# STM32MP23_CM33 register map
File version: 1.2
CPU: CM33 r0p1, little endian, MPU, FPU, vendor SysTick, 8 interrupt priority bits
Registers are 32-bit, read-write, reset 0x0 unless marked. A register's access mark holds for its fields unless they carry their own. Offsets are from the block's base; [hi:lo] are bit positions; {n}, {i} and the like mark numbered series.

## USB3DR (part 2 of 4) — USB3DR register block
Base 0x48300000
Same registers: USB3DR_S 0x58300000
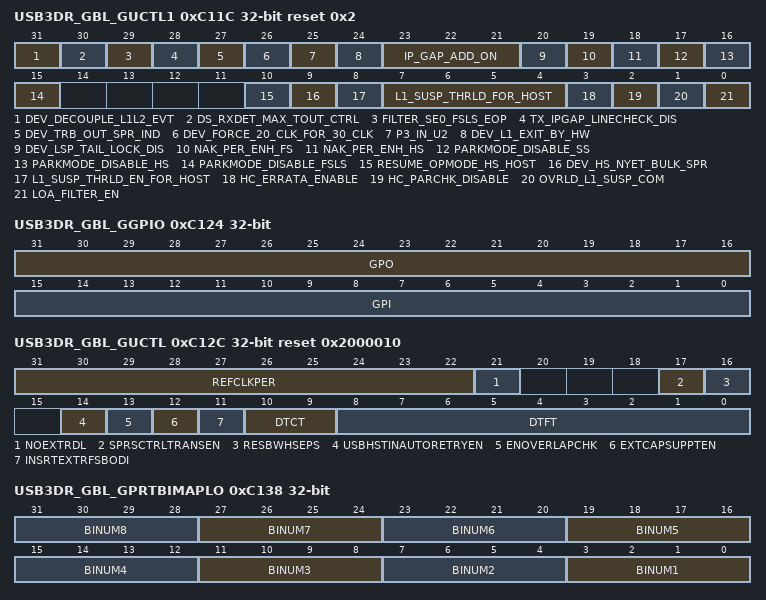
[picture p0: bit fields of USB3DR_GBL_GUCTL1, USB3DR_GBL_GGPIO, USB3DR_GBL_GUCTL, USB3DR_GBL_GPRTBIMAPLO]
0xC11C USB3DR_GBL_GUCTL1 reset 0x2 — USB3DR global user control register 1
  [31] DEV_DECOUPLE_L1L2_EVT — DEV_DECOUPLE_L1L2_EVT This bit is applicable for device mode only. If this feature is enabled, L1 suspend and wake events have individual controls to enable/mask them. This feature must be enabled in order to get L1 (LPM) events separately and not combined with L2 events when operating in 2.0 speeds.
    0=Default behavior, no change in device events L1/L2U3, events are not decoupled (old behavior of v2.90a and before); 1=Feature enabled, L1 and L2 events are separated when operating in 2.0 mode. Separate event enable bits for L1 suspend and wake events.
  [30] DS_RXDET_MAX_TOUT_CTRL — DS_RXDET_MAX_TOUT_CTRL This bit is used to control the tsubRxDetectTimeoutDFP/sub timer for the SuperSpeed link. This bit is used only in Host mode. For more details, refer to ECN020 of [USB3].
    0=Default behavior; 12ms is used as tsubRxDetectTimeoutDFP/sub; 1=120ms is used as the tsubRxDetectTimeoutDFP/sub
  [29] FILTER_SE0_FSLS_EOP — FILTER_SE0_FSLS_EOP This bit is applicable for FS/LS operation. If this feature is enabled, then SE0 on the linestate is validated for 2 consecutive utmi/ulpi clock edges for EOP detection. This feature is applicable only in FS in device mode and FS/LS mode of operation in host mode. Device mode: FS - If GUCTL1.FILTER_SE0_FSLS_EOP is set, then for device LPM handshake, the core ignores single SE0 glitch on the linestate during transmit. Only two or more SE0 areconsidered as a valid EOP on FS. Host mode: FS/LS - If GUCTL1.FILTER_SE0_FSLS_EOP is set, then the core ignores single SE0 glitch on the linestate during transmit. Only 2 or more SE0 are considered as a valid EOP on FS/LS port. Enable this feature if the LineState has SE0 glitches during transmission. This bit is quasi-static, that is it must not be changed during device operation.
    0=Default behavior, no change in linestate check for SE0 detection in FS/LS; 1=Feature enabled, FS/LS SE0 is filtered for 2 clocks for detecting EOP
  [28] TX_IPGAP_LINECHECK_DIS — TX_IPGAP_LINECHECK_DIS This bit is applicable for HS operation of u2mac. If this feature is enabled, then the 2.0 MAC operating in HS ignores the UTMI/ULPI linestate during the transmit of a token (during token-to-token and token-to-data IPGAP). When enabled, the controller implements a fixed 40-bit TxEndDelay after the packet is given on UTMI and ignores the linestate during this time. This feature is applicable only in HS mode of operation. Device mode: If GUCTL1.TX_IPGAP_LINECHECK_DIS is set, then for device LPM handshake, the core ignores the linestate after TX and wait for fixed clocks (40 bit times equivalent) after transmitting ACK on utmi. Host mode: If GUCTL1.TX_IPGAP_LINECHECK_DIS is set, then the ipgap between token-to-token or token-to-data is extended by a 40-bit time delay (TXENDDELAY), and linestate is ignored during this 40-bit time delay. Enable this bit if the linestate does not reflect the expected line state (J) during transmission. This bit is quasi-static, that is, it must not be changed during device operation.
    0=Default behavior, no change in linestate check; 1=Feature enabled, 2.0 MAC disables linestate check during HS transmit
  [27] DEV_TRB_OUT_SPR_IND — DEV_TRB_OUT_SPR_IND This bit is applicable for Device mode only (and ignored in Host mode). If the device application (software/hardware) wants to know if a short packet was received for an OUT in the TRB status itself, then this feature can be enabled, so that a bit is set in the TRB writeback in the buf_size dword. Bit[26] of buf_size is set during an OUT transfer TRB write back if this is the last TRB used for that transfer descriptor. This bit is quasi-static, that is, it must not be changed during device operation.
    0=Default behavior, no change in TRB status dword; 1=Feature enabled, OUT TRB status indicates short packet
  [26] DEV_FORCE_20_CLK_FOR_30_CLK — DEV_FORCE_20_CLK_FOR_30_CLK This bit is applicable (and to be set) for device mode only (DCFG.Speed different SS). In the 3.0 device core, if the core is programmed to operate in 2.0 only (that is, device speed is programmed to 2.0 speeds in DCFG[Speed]), then setting this bit makes the internal 2.0 (utmi/ulpi) clock to be routed as the 3.0 (pipe) clock. Enabling this feature disables the pipe3 clock when forcibly operating in 2.0 device mode. Note: When using this feature, all pipe3 inputs must be in inactive mode. In particular, the pipe3 clocks must not be running and the pipe3_phystatus_async must be tied to 0. This bit should not be set if the core is programmed to operate in SuperSpeed mode (even when it falls back to 2.0). Note: This bit is quasi-static, that is it must not be changed during operation. Note: If the parameter 'USB3DR_REMOVE_PIPE_CLK_MUX_FOR_20_MODE' is enabled, the muxing of 2.0 clock/signals to pipe_clk/signals must be done outside the controller for this feature to work.
    0=Default behavior, uses 3.0 clock when operating in 2.0 mode; 1=Feature enabled
  [25] P3_IN_U2 — P3_IN_U2 Setting this bit enables P3 Power state when the SuperSpeed link is in U2. Another Power saving option. Check with the PHY vendor before enabling this option. When setting this bit to 1 in order to enable P3 in P2, GUSB3PIPECTL[27] should be set to 0 to make sure that the U2 exit is attempted in P0. This bit should be set only when GCTL.SOFITPSYNC=1 or GFLADJ.GFLADJ_REFCLK_LPM_SEL=1.
    0=Default behavior. When SuperSpeed link is in U2, PowerState P2 is attempted on the PIPE interface.; 1=When SuperSpeed link is in U2, PowerState P3 is attempted if GUSB3PIPECTL[17] is set
  [24] DEV_L1_EXIT_BY_HW — DEV_L1_EXIT_BY_HW This bit is applicable for Device mode (2.0) only. This field enables device controller sending remote wakeup for L1 if the device becomes ready for sending/accepting data when in L1 state. If the host expects the device to send remote wakeup signaling to resume after going into L1 in flow controlled state, then this bit can be set to send the remote wake signal automatically when the device controller becomes ready. This hardware remote wake feature is applicable only to bulk and interrupt transfers, and not for Isoch/Control When control transfers are in progress, the LPM is rejected (NYET response). Only after control transfers are completed (either with ACK/STALL), LPM is accepted For Isoch transfers, the host needs to do the wakeup and start the transfer. Device controller does not remote-wakeup when Isoch endpoints get ready. The device software needs to keep the GUSB2PHYCFG[EnblSlpM] reset in order to keep the PHY clock to be running for keeping track of SOF intervals. When L1 hibernation is enabled, the controller does not do automatic exit for hibernation requests through L1. This bit is quasi-static, that is, it must not be changed during device operation.
    0=Default behavior, disables device L1 hardware exit logic; 1=feature enabled
  [23:21] IP_GAP_ADD_ON — This register field is used to add up to the default inter packet gap setting in the USB 2.0 MAC. This should be programmed to a non zero value only in case the default inter packet delay calculations in the USB 2.0 MAC module needs to be increased.
  [20] DEV_LSP_TAIL_LOCK_DIS — DEV_LSP_TAIL_LOCK_DIS This is a bug fix for STAR 9000716195 that affects the CSP mode for OUT endpoints in device mode. The issue is that tail TRB index is not synchronized with the cache scratchpad bytecount update. If the fast-forward request comes in-between the bytecount update on a newly fetched TRB and the tail-index write update in TPF, the RDP works on an incorrect tail index and misses the byte count decrement for the newly fetched TRB in the fast-forwarding process. This fix needs to be present all the times.
    0=Default behavior, enables device lsp lock logic for tail TRB update; 1=Bug fix disabled
  [19] NAK_PER_ENH_FS — NAK_PER_ENH_FS If a periodic endpoint is present, and if a bulk endpoint which is also active is being NAKed by the device, then this may result in a decrease in performance of another Full speed bulk endpoint which is ACKed by the device. Setting this bit to 1 enables the host controller to schedule more transactions to the async endpoints (bulk/control) and hence improves the performance of the bulk endpoint. This control bit should be enabled only if the existing performance with the default setting is not sufficient for the FullSpeed application. Setting this bit only controls, and is only required for full speed transfers.
    1=Enables performance enhancement for FS async endpoints in the presence of NAKs; 0=Enhancement not applied
  [18] NAK_PER_ENH_HS — NAK_PER_ENH_HS If a periodic endpoint is present, and if a bulk endpoint which is also active is being NAKed by the device, then this may result in decrease in performance of another high-speed bulk endpoint which is ACKed by the device. Setting this bit to 1 enables the host controller to schedule more transactions to the async endpoints (bulk/control) and hence improves the performance of the bulk endpoint. This control bit should be enabled only if the existing performance with the default setting is not sufficient for the HighSpeed application. Setting this bit only controls, and is only required for high-speed transfers.
    1=Enables performance enhancement for HS async endpoints in the presence of NAKs; 0=Enhancement not applied
  [17] PARKMODE_DISABLE_SS — PARKMODE_DISABLE_SS This bit is used only in Host mode, and is for debug purpose only. When this bit is set to 1 all SS bus instances in park mode are disabled.
  [16] PARKMODE_DISABLE_HS — PARKMODE_DISABLE_HS This bit is used only in Host mode. When this bit is set to 1 all HS bus instances park mode are disabled. To improve performance in park mode, the xHCI scheduler queues in three requests of 4 packets each for high-speed asynchronous endpoints in a micro-frame. But if a device is slow and if it NAKs more than 3 times, then it is rescheduled only in the next micro-frame. This may decrease the performance of a slow device even further. In a few high-speed devices (such as Sandisksup/sup Cruzer Blade 4GB VID:1921, PID:21863 and Flex Drive VID:3744, PID:8552) when an IN request is sent within 900ns of the ACK of the previous packet, these devices send a NAK. When connected to these devices, if required, the software can disable the park mode if a performance drop is observed in the system. When park mode is disabled, pipelining of multiple packet is disabled and instead one packet at a time is requested by the scheduler. This allows up to 12 NAKs in a micro-frame and improves performance of these slow devices.
  [15] PARKMODE_DISABLE_FSLS — PARKMODE_DISABLE_FSLS This bit is used only in host mode, and is for debug purpose only. When this bit is set to 1 all FS/LS bus instances in park mode are disabled.
  [10] RESUME_OPMODE_HS_HOST — RESUME_OPMODE_HS_HOST This bit is used only in host mode, and is for USB 2.0 opmode behavior in HS Resume. When this bit is set to '1', the UTMI/ULPI opmode is changed to 'normal' along with HS terminations after EOR. This option is to support certain legacy UTMI/ULPI PHYs. When this bit is set to '0', the UTMI/ULPI opmode is changed to 'normal' 2us after HS terminations change after EOR. This is the default behavior.
  [9] DEV_HS_NYET_BULK_SPR — DEV_HS_NYET_BULK_SPR This bit is applicable for device mode only (and ignored in Host mode) to be used in 2.0 operation. If this bit is set, the device core sends NYET response instead of ACK response for a successfully received bulk OUT short packet. If NYET is sent after receiving short packet, then the host would PING before sending the next OUT. This improves the performance as well as clears up the buffer/cache on the host side. Internal to the device core, short packet (SPR1) processing takes some time, and during this time, the USB is flow controlled. With NYET response instead of ACK on short packet, the host does not send another OUT-DATA without pinging in HS mode. This bit is quasi-static, that is, it must not be changed during device operation.
    0=Default behavior, no change in device response; 1=Feature enabled, HS bulk OUT short packet gets NYET response
  [8] L1_SUSP_THRLD_EN_FOR_HOST — L1_SUSP_THRLD_EN_FOR_HOST This bit is used only in Host mode. The host controller asserts the utmi_l1_suspend_n and utmi_sleep_n output signals as follows: The controller asserts the utmi_l1_suspend_n signal to put the PHY into deep Low-power mode in L1 when both of the following are true: The HIRD/BESL value used is greater than or equal to the value in L1_SUSP_THRLD_FOR_HOST field. The L1_SUSP_THRLD_EN_FOR_HOST bit is set to 1. The controller asserts utmi_sleep_n on L1 when one of the following is true: The HIRD/BESL value used is less than the value in L1_SUSP_THRLD_FOR_HOST field. The L1_SUSP_THRLD_EN_FOR_HOST bit is set to 0.
  [7:4] L1_SUSP_THRLD_FOR_HOST — L1_SUSP_THRLD_FOR_HOST This field is effective only when the L1_SUSP_THRLD_EN_FOR_HOST bit is set to 1. For more details, refer to the description of the L1_SUSP_THRLD_EN_FOR_HOST bit.
  [3] HC_ERRATA_ENABLE — Host ELD Enable (HELDEn) When this bit is set to 1, it enables the exit latency delta (ELD) support defined in the [xHCI] errata. This bit is used only in the host mode. This bit has to be set to 1 in Host mode.
  [2] HC_PARCHK_DISABLE — Host parameter check disable (HParChkDisable) When this bit is set to 0 (by default), the xHC checks that the input slot/EP context fields comply to the xHCI specification. Upon detection of a parameter error during command execution, the xHC generates an event TRB with completion code indicating 'PARAMETER ERROR'. When the bit is set to '1', the xHC does not perform parameter checks and does not generate 'PARAMETER ERROR' completion code.
  [1] OVRLD_L1_SUSP_COM — OVRLD_L1_SUSP_COM If this bit is set, the utmi_l1_suspend_com_n is overloaded with the utmi_sleep_n signal. This bit is usually set if the PHY stops the port clock during L1 sleep condition. Note: The recommended connection for the SUSPENDM/SLEEPM signals to the PHY with respect to this bit is as follows. Note: For non-zero ports: Note: Connect: Note: - utmi_sleep_n[n] to SLEEPM[n] Note: - (utmi_suspend_n[n] & utmi_l1_suspend_n[n]) to SUSPENDM[n] Note: - USB2 PHYCLK[n] to utmi_clk[n] Note: GUCTL1.OVRLD_L1_SUSP_COM impacts only Port0. Note: For Port0: Note: For Synopsys PHY, GUSB2PHYCFGn.U2_FREECLK_EXISTS=1. With this connection, the PHY keeps PLL active so that FREECLK is always available irrespective of suspend/sleep. Note: - Connect USB2 PHY COMMONONN to 0. Note: - Connect utmi_sleep_n[0] to SLEEPM[0]. Note: - Connect (utmi_suspend_n[0] & utmi_l1_suspend_n[0]) to SUSPENDM[0]. Note: - Connect USB2 PHY FREECLK to utmi_clk[0]. Note: - Leave utmi_suspend_com_n, utmi_l1_suspend_com_n unconnected. Note: - GUCTL1.OVRLD_L1_SUSP_COM can be set to any value. Note: For Third Party PHY, Note: GUSB2PHYCFGn.U2_FREECLK_EXISTS=0. With this connection the PHY can shut off all the clocks when the required conditions are met (such as GUSB2PHYCFGn[8,6], GUCTL1[1], GFLADJ[23], GCTL[10], suspend condition, HW LPM enable). Note: - Connect -utmi_suspend_com_n to SUSPENDM[0] (or equivalent). Note: - Connect -utmi_l1_suspend_com_n to SLEEPM[0] (or equivalent). Note: - Connect PHYCLK0 (first port clock) to utmi_clk[0]. Note: - Leave utmi_suspend_n[0], utmi_l1_suspend_ n[0], utmi_sleep_n[0] unconnected. Note: - Set GUCTL1.OVRLD_L1_SUSP_COM to 0b1.
  [0] LOA_FILTER_EN — LOA_FILTER_EN If this bit is set, the USB 2.0 port babble is checked at least three consecutive times before the port is disabled. This prevents false triggering of the babble condition when using low quality cables. Note: This bit is valid only in host mode.
0xC120 USB3DR_GBL_GSNPSID ro reset 0x5533330B — USB3DR global Synopsys ID register
  [31:0] SYNOPSYSID — Synopsys ID SynopsysID[31:16] indicates core identification number. 0x5533 is ASCII for U3 (USB3DR). SynopsysID[15:0] indicates the release number.
0xC124 USB3DR_GBL_GGPIO — USB3DR global general purpose input/output register
  [31:16] GPO — General purpose output This field value is driven out on the gp_out[15:0] core output port.
  [15:0] GPI ro — General purpose input This field read value reflects the gp_in[15:0] core input value. Note: Register bit-bash test should not check for reset value of this field since its not predictable; depends on the gp_in port.
0xC128 USB3DR_GBL_GUID reset 0x12345678 — USB3DR global user ID register
  [31:0] USERID — USERID Application programmable ID field.
0xC12C USB3DR_GBL_GUCTL reset 0x2000010 — USB3DR global user control register
  [31:22] REFCLKPER — REFCLKPER This field indicates in terms of nano seconds the period of ref_clk. The default value of this register is set to 0x8 (8ns/125MHz). This field needs to be updated during power-on initialization, if GCTL.SOFITPSYNC or GFLADJ.GFLADJ_REFCLK_LPM_SEL is set to 1. The programmable maximum value is 62ns, and the minimum value is 8ns. A reference clock with a period that is an integer multiple must be used, so that ITP can meet the jitter margin of 32ns. The allowable ref_clk frequencies whose period is not integer multiple are 16/17/19.2/24/39.7MHz. This field must not be set to 0 at any time. If this feature should never be used, this field should be kept at its default value 0x8.
  [21] NOEXTRDL — No extra delay between SOF and the first Packet(NoExtrDl) Some HS devices misbehave when the host sends a packet immediately after a SOF. However, adding an extra delay between a SOF and the first packet can reduce the USB data rate and performance. This bit is used to control whether the host must wait for 2 microseconds before it sends the first packet after a SOF, or not. User can set this bit to 1 to improve the performance if those problematic devices are not a concern in the user's host environment.
    0=Host waits for 2 microseconds after a SOF before it sends the first USB packet; 1=Host does not wait after a SOF before it sends the first USB packet
  [17] SPRSCTRLTRANSEN — Sparse control transaction enable Some devices are slow in responding to control transfers. Scheduling multiple transactions in one microframe/frame can cause these devices to misbehave. If this bit is set to 1, the host controller schedules transactions for a control transfer in different microframes/frames.
  [16] RESBWHSEPS — Reserving 85% bandwidth for HS periodic EPs (ResBwHSEPS) By default, HC reserves 80% of the bandwidth for periodic EPs. If this bit is set, the bandwidth is relaxed to 85% to accommodate two high-speed, high-bandwidth ISOC EPs. USB 2.0 required 80% bandwidth allocated for ISOC traffic. If two high-bandwidth ISOC devices (HD webcams) are connected, and if each requires 1024-bytes X 3 packets per microframe, then the bandwidth required is around 82%. If this bit is set, then it is possible to connect two webcams of 1024Bytes X 3 paylod per microframe each. Otherwise the resolution of the webcams may have to be reduced. This bit is valid in Host and DRD configuration and is used in Host mode operation only. Ignore this bit in device mode.
  [14] USBHSTINAUTORETRYEN — Host IN auto retry (USBHstInAutoRetryEn) When set, this field enables the auto retry feature. For IN transfers (non-isochronous) that encounter data packets with CRC errors or internal overrun scenarios, the auto retry feature causes the Host core to reply to the device with a non-terminating retry ACK (that is, an ACK transaction packet with Retry = 1 and NumP different 0). If the auto retry feature is disabled (default), the core responds with a terminating retry ACK (that is, an ACK transaction packet with Retry=1 and NumP=0). Note: When enabling auto retry feature, if the system latency is large enough to cause the internal PSQ full (PSQ can be full as the result of messages not being processed because of pending fetches before flushing the TxQ due to NRDY/ERDY conditions), then the host controller can generate a transaction error.
    0=Auto retry disabled; 1=Auto retry enabled
  [13] ENOVERLAPCHK — Enable check for LFPS overlap during remote Ux exit: If this bit is set to,
    1=The SuperSpeed link when exiting U1/U2/U3 waits for either the remote link LFPS or TS1/TS2 training symbols before it confirms that the LFPS handshake is complete. This is done to handle the case where the LFPS glitch causes the link to start exiting from the low power state. Looking for the LFPS overlap makes sure that the link partner also sees the LFPS.; 0=When the link exits U1/U2/U3 because of a remote exit, it does not look for an LFPS overlap
  [12] EXTCAPSUPPTEN — External extended capability support enable (ExtCapSuptEN) When set, this field enables extended capabilities to be implemented outside the core. When the ExtCapSupEN is set and the debug capability is enabled, the next capability pointer in 'Debug Capability' returns 16. A read to the first dword of the last internal extended capability (the 'xHCI supported Protocol Capability for USB 3.0' when the debug capability is not enabled) returns a value of 4 in the next capability pointer field. This indicates to software that there is another capability, 4 dwords after this capability (for example, at address N+16 where N is the address of this dword). If enabled, an external address decoder that snoops the xHC slave interface must be implemented. If it sees an access to N+16 or greater, the slave access is re-routed to a piece of hardware which returns the external capability pointer register of the new capability and also handles reads/writes to this new capability and the side effects. If disabled, a read to the first dword of the last internal extended capability returns 0 in the next capability pointer field. This indicates there are no more capabilities.
  [11] INSRTEXTRFSBODI — Insert extra delay between FS bulk OUT transactions (InsrtExtrFSBODl) Some FS devices are slow to receive bulk OUT data and can get stuck when there are consecutive bulk OUT transactions with short inter-transaction delays. This bit is used to control whether the host inserts extra delay between consecutive bulk OUT transactions to a FS endpoint. Note: Setting this bit to one reduces the bulk OUT transfer performance for most of the FS devices.
    0=Host does not insert extra delay between consecutive bulk OUT transactions to a FS endpoint; 1=Host inserts about 12 us extra delay between consecutive bulk OUT transactions to a FS endpoint to work around the device issue
  [10:9] DTCT — Device timeout coarse tuning (DTCT) This field is a Host mode parameter which determines how long the host waits for a response from device before considering a timeout. The core first checks the DTCT value. If it is 0, then the timeout value is defined by the DTFT. If it is non-zero, then it uses the following timeout values: Note: When the system latency is larger than the programmed DTCT/DTFT value, if the host controller is not able to accept certain transactions on the bus (because of system bus delays), the controller may not release header credits which in turn can cause the host to report a transaction error. Therefore, program this value to be larger than the system delay.
    0=0 us → use DTFT value instead; 1=0.5ms; 2=1.5ms; 3=6.5ms
  [8:0] DTFT — Device timeout fine tuning (DTFT) This field is a Host mode parameter which determines how long the host waits for a response from device before considering a timeout. For the DTFT field to take effect, DTCT must be set to 0b00. The DTFT value is the number of 125MHz clocks 256 to count before considering a device timeout. The minimum value of DTFT is 2. For example, if the mac3_clk is 125MHz clk (8ns period), this is calculated as follows: (DTFT value) 256 (8ns) Quick Reference: - if DTFT = 0x2, 2 × 256 × 8 = 4 us timeout - if DTFT = 0x5, 5 × 256 × 8 = 10 us timeout - if DTFT = 0xA, 10 × 256 × 8 = 20 us timeout - if DTFT = 0x10, 16 × 256 × 8 = 32 us timeout - if DTFT = 0x19, 25 × 256 × 8 = 51 us timeout - if DTFT = 0x31, 49 × 256 × 8 = 100 us timeout - if DTFT = 0x62, 98 × 256 × 8 = 200 us timeout Note: When SSIC is enabled, in HS_G1_G2_G3 mode, and ssic_soc_pa_clk_freq = 0b01, then DTFT value must be calculated for 156.25 MHz clock, for example, for equivalent delay of 32 us DTFT value must be 0x14. Note: When the system latency is larger than the programmed DTCT/DTFT value, if the host controller is not able to accept certain transactions on the bus (because of system bus delays), the controller may not release header credits which in turn can cause the host to report a transaction error. Therefore, program this value to be larger than the system delay.
0xC130 USB3DR_GBL_GBUSERRADDRLO ro — USB3DR global bus error address register - low
  [31:0] BUSERRADDR — Bus address low (BusAddrLo) This register contains the lower 32 bits of the first bus address that encountered a device bus error. It is valid when the GSTS.BusErrAddrVld field is 1. It can only be cleared by resetting the core. Note: Only supported in AHB and AXI configurations.
0xC134 USB3DR_GBL_GBUSERRADDRHI ro — USB3DR gobal bus error address register - high
  [31:0] BUSERRADDR — Bus address high (BusAddrHi) This register contains the higher 32 bits of the first bus address that encountered a device bus error. It is valid when the GSTS.BusErrAddrVld field is 1. It can only be cleared by resetting the core. Note: Only supported in AHB and AXI configurations.
0xC138 USB3DR_GBL_GPRTBIMAPLO — USB3DR global SS port to bus instance mapping register - low
  [4n-1:4n-4] BINUM{n} (n=1..8) — SS USB instance number for port {n}. Application programmable ID field.
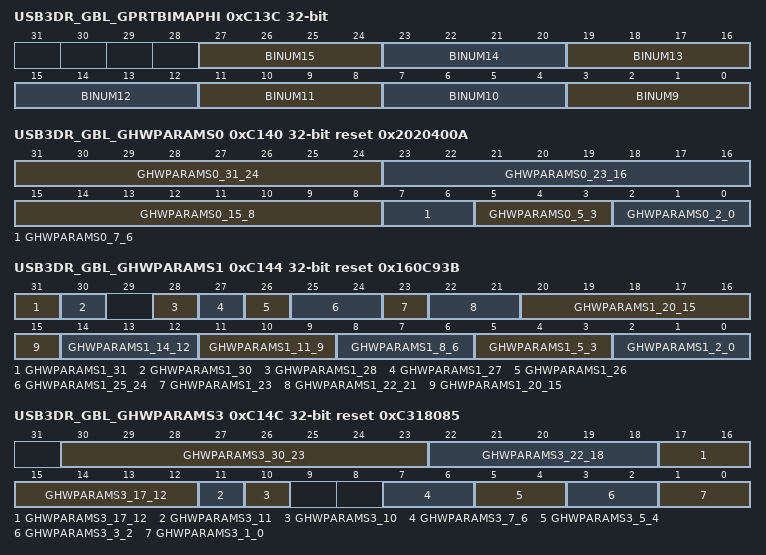
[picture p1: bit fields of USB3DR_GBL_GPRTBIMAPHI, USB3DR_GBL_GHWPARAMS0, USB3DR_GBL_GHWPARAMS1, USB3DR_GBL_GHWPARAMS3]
0xC13C USB3DR_GBL_GPRTBIMAPHI — USB3DR global SS port to bus instance mapping register - high
  [4n-33:4n-36] BINUM{n} (n=9..15) — SS USB instance number for port {n}. Application programmable ID field.
0xC140 USB3DR_GBL_GHWPARAMS0 ro reset 0x2020400A — USB3DR global hardware parameters register 0
  [31:24] GHWPARAMS0_31_24 — USB3DR_AWIDTH
  [23:16] GHWPARAMS0_23_16 — USB3DR_SDWIDTH
  [15:8] GHWPARAMS0_15_8 — USB3DR_MDWIDTH
  [7:6] GHWPARAMS0_7_6 — USB3DR_SBUS_TYPE
  [5:3] GHWPARAMS0_5_3 — USB3DR_MBUS_TYPE
  [2:0] GHWPARAMS0_2_0 — USB3DR_MODE
0xC144 USB3DR_GBL_GHWPARAMS1 ro reset 0x160C93B — USB3DR global hardware parameters register 1
  [31] GHWPARAMS1_31 — USB3DR_EN_DBC
  [30] GHWPARAMS1_30 — USB3DR_RM_OPT_FEATURES
  [28] GHWPARAMS1_28 — USB3DR_RAM_BUS_CLKS_SYNC
  [27] GHWPARAMS1_27 — USB3DR_MAC_RAM_CLKS_SYNC
  [26] GHWPARAMS1_26 — USB3DR_MAC_PHY_CLKS_SYNC
  [25:24] GHWPARAMS1_25_24 — USB3DR_EN_PWROPT
  [23] GHWPARAMS1_23 — USB3DR_SPRAM_TYP
  [22:21] GHWPARAMS1_22_21 — USB3DR_NUM_RAMS
  [20:15] GHWPARAMS1_20_15 — USB3DR_DEVICE_NUM_INT
  [14:12] GHWPARAMS1_14_12 — USB3DR_ASPACEWIDTH
  [11:9] GHWPARAMS1_11_9 — USB3DR_REQINFOWIDTH
  [8:6] GHWPARAMS1_8_6 — USB3DR_DATAINFOWIDTH
  [5:3] GHWPARAMS1_5_3 — USB3DR_BURSTWIDTH-1
  [2:0] GHWPARAMS1_2_0 — USB3DR_IDWIDTH-1
0xC148 USB3DR_GBL_GHWPARAMS2 ro reset 0x12345678 — USB3DR global hardware parameters register 2
  [31:0] GHWPARAMS2_31_0 — USB3DR_USERID
0xC14C USB3DR_GBL_GHWPARAMS3 ro reset 0xC318085 — USB3DR global hardware parameters register 3
  [30:23] GHWPARAMS3_30_23 — USB3DR_CACHE_TOTAL_XFER_RESOURCES
  [22:18] GHWPARAMS3_22_18 — USB3DR_NUM_IN_EPS
  [17:12] GHWPARAMS3_17_12 — USB3DR_NUM_EPS
  [11] GHWPARAMS3_11 — USB3DR_ULPI_CARKIT
  [10] GHWPARAMS3_10 — USB3DR_VENDOR_CTL_INTERFACE
  [7:6] GHWPARAMS3_7_6 — USB3DR_HSPHY_DWIDTH
  [5:4] GHWPARAMS3_5_4 — USB3DR_FSPHY_INTERFACE
  [3:2] GHWPARAMS3_3_2 — USB3DR_HSPHY_INTERFACE
  [1:0] GHWPARAMS3_1_0 — USB3DR_SSPHY_INTERFACE
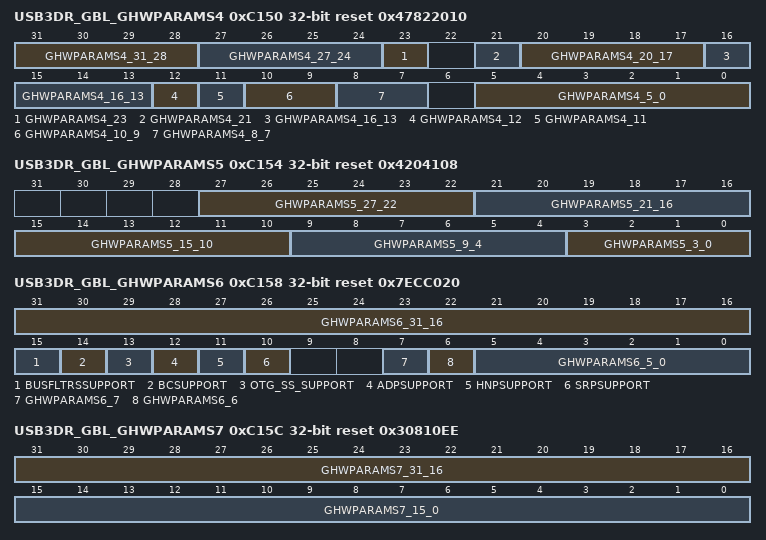
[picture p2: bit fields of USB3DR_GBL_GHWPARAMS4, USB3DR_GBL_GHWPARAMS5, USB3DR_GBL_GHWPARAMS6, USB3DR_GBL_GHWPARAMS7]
0xC150 USB3DR_GBL_GHWPARAMS4 ro reset 0x47822010 — USB3DR global hardware parameters register 4
  [31:28] GHWPARAMS4_31_28 — USB3DR_BMU_LSP_DEPTH
  [27:24] GHWPARAMS4_27_24 — USB3DR_BMU_PTL_DEPTH-1
  [23] GHWPARAMS4_23 — USB3DR_EN_ISOC_SUPT
  [21] GHWPARAMS4_21 — USB3DR_EXT_BUFF_CONTROL
  [20:17] GHWPARAMS4_20_17 — USB3DR_NUM_SS_USB_INSTANCES
  [16:13] GHWPARAMS4_16_13 — USB3DR_HIBER_SCRATCHBUFS Number of external scratchpad buffers the core requires to save its internal state in the device mode. Each buffer is assumed to be 4KBytes. The scratchpad buffer array must have this many buffer pointers.
  [12] GHWPARAMS4_12 — USB3DR_EN_SSIC Note: When the USB3DR_NUM_SSIC_PORTS parameter is set to zero, this bit is Reserved.
    0=if USB3DR_EN_SSIC=0; 1=if USB3DR_EN_SSIC different 0
  [11] GHWPARAMS4_11 — USB3DR_SSIC_NON_SNPS_MPHY This field indicates whether Synopsys M-PHY or a third party M-PHY is used with SSIC ports. Note: When the USB3DR_NUM_SSIC_PORTS parameter is set to zero, this bit is Reserved.
    0=Synopsys M-PHY; 1=Third party M-PHY
  [10:9] GHWPARAMS4_10_9 — USB3DR_SSIC_GEAR This field indicates USB3DR_SSIC_GEAR parameter value chosen by the user. Note: When the USB3DR_NUM_SSIC_PORTS parameter is set to zero, this field is Reserved.
    1=HS-G1; 2=HS-G2; 3=HS-G3
  [8:7] GHWPARAMS4_8_7 — USB3DR_NUM_SSIC_NUM_LANE This bit indicates USB3DR_SSIC_NUM_LANE parameter value chosen by the user. Note: When the USB3DR_NUM_SSIC_PORTS parameter is set to zero, this field is Reserved.
    0=4 lanes; 1=1 lane; 2=2 lanes
  [5:0] GHWPARAMS4_5_0 — USB3DR_CACHE_TRBS_PER_TRANSFER
0xC154 USB3DR_GBL_GHWPARAMS5 ro reset 0x4204108 — USB3DR global hardware parameters register 5
  [27:22] GHWPARAMS5_27_22 — USB3DR_DFQ_FIFO_DEPTH
  [21:16] GHWPARAMS5_21_16 — USB3DR_DWQ_FIFO_DEPTH
  [15:10] GHWPARAMS5_15_10 — USB3DR_TXQ_FIFO_DEPTH
  [9:4] GHWPARAMS5_9_4 — USB3DR_RXQ_FIFO_DEPTH
  [3:0] GHWPARAMS5_3_0 — USB3DR_BMU_BUSGM_DEPTH
0xC158 USB3DR_GBL_GHWPARAMS6 ro reset 0x7ECC020 — USB3DR global hardware parameters register 6
  [31:16] GHWPARAMS6_31_16 — USB3DR_RAM0_DEPTH
  [15] BUSFLTRSSUPPORT — USB3DR_EN_BUS_FILTERS
  [14] BCSUPPORT — USB3DR_EN_BC
  [13] OTG_SS_SUPPORT — OTG 3.0 support enabled This bit indicates whether the parameter USB3DR_EN_OTG is set to 2. In other words, it indicates whether the USB3DR core supports OTG 3.0.
    0=No OTG 3.0 support; 1=Supports OTG 3.0
  [12] ADPSUPPORT — USB3DR_EN_ADP
  [11] HNPSUPPORT — RSP/HNP support enabled The application uses this bit to determine the USB3DR RSP/HNP support. This bit is enabled only if HNP mode was specified for HNP mode of operation in coreConsultant (parameter USB3DR_EN_OTG is not 0, and USB3DR_MODE is DRD). Otherwise, it reads as 0.
    0=B_0x0_USB3DR_EN_OTG_EQUAL2 (RSP and HNP support is not enabled. The only exception for this rule is for SSPC-OTG devices where RSP support is not enabled, but HNP support is enabled (refer to the OCFG.SSPC-OTG bit.)); 1=B_0x1_USB3DR_EN_OTG_EQUAL2 (RSP and HNP support is enabled)
  [10] SRPSUPPORT — SRP support enabled The application uses this bit to determine the USB3DR SRP support. This bit is 1 when the parameter USB3DR_EN_OTG is not 0.
    0=SRP support is not enabled;; 1=SRP support is enabled;
  [7] GHWPARAMS6_7 — USB3DR_EN_FPGA
  [6] GHWPARAMS6_6 — USB3DR_EN_DBG_PORTS
  [5:0] GHWPARAMS6_5_0 — USB3DR_PSQ_FIFO_DEPTH
0xC15C USB3DR_GBL_GHWPARAMS7 ro reset 0x30810EE — USB3DR global hardware parameters register 7
  [31:16] GHWPARAMS7_31_16 — USB3DR_RAM2_DEPTH
  [15:0] GHWPARAMS7_15_0 — USB3DR_RAM1_DEPTH
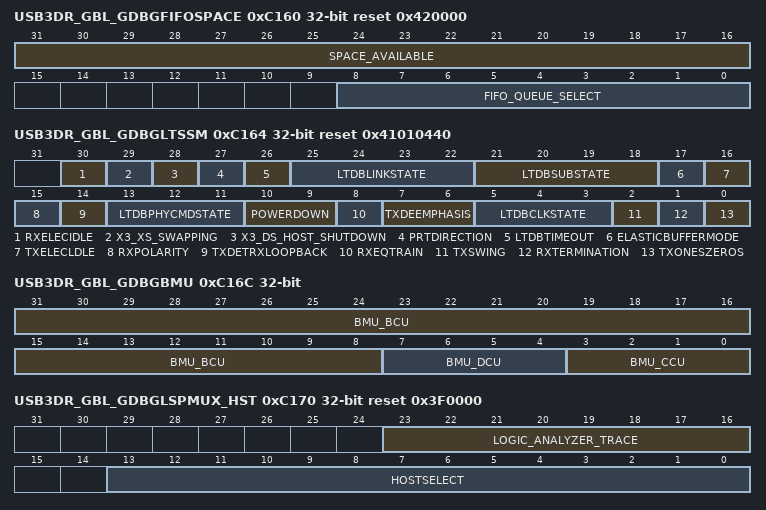
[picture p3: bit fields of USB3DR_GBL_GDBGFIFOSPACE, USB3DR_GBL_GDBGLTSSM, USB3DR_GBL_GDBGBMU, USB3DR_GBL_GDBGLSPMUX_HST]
0xC160 USB3DR_GBL_GDBGFIFOSPACE reset 0x420000 — USB3DR global debug queue/FIFO space available register
  [31:16] SPACE_AVAILABLE ro
  [8:0] FIFO_QUEUE_SELECT — FIFO/queue select and port select FIFO_QUEUE_SELECT[8:5] indicates the FIFO/queue type FIFO_QUEUE_SELECT[4:0] indicates the FIFO/queue number For example 00100001 refers to RxFIFO_1 and 01011110 refers to TxReqQ_30. 00011111 to 00000000: TxFIFO_31 to TxFIFO_0 00111111 to 00100000: RxFIFO_31 to RxFIFO_0 01011111 to 01000000: TxReqQ_31 to TxReqQ_0 01111111 to 01100000: RxReqQ_31 to RxReqQ_0 10011111 to 10000000: RxInfoQ_31 to RxInfoQ_0 11011111 to 11100000: DescFetchQ_31 to DescFetchQ_0 11111111 to 11100000: WriteBack/EventQ_31 to WriteBack/EventQ_0 00000111 to 00000000: AuxEventQ_7 to AuxEventQ_0 (if EN_SEPARATE_DESC_QUEUES=1) FIFO_QUEUE_SELECT[3:0] selects the port-number when accessing GDBGLTSSM register.
    160=DescFetchQ_0 (for backwards compatibility); 161=EventQ_0 (for backwards compatibility); 162=ProtocolStatusQ_0
0xC164 USB3DR_GBL_GDBGLTSSM ro reset 0x41010440 — USB3DR global debug LTSSM register
  [30] RXELECIDLE — RxElecidle For description of RxElecIdle, see [PIPE].
  [29] X3_XS_SWAPPING — a3_ds_swapping/a3_us_swapping/b3_ds_swapping/b3_us_swapping Interpret this field based on the port direction. Note: This bit is applicable only for OTG 3.0 mode of operation and is Reserved for other modes.
  [28] X3_DS_HOST_SHUTDOWN — a3_ds_host_shutdown/b3_ds_host_shutdown Note: This bit is applicable only for OTG 3.0 mode of operation and is Reserved for other modes.
  [27] PRTDIRECTION — Port direction Note: This bit is applicable only for OTG 3.0 mode of operation and is Reserved for other modes.
    0=Upstream; 1=Downstream
  [26] LTDBTIMEOUT — LTDB Timeout (LTDBTimeout)
  [25:22] LTDBLINKSTATE — LTDB link state (LTDBLinkState)
  [21:18] LTDBSUBSTATE — LTDB sub-state (LTDBSubState)
  [17] ELASTICBUFFERMODE — Elastic buffer mode (ElasticBufferMode) For field definition, refer to Table 5-3 of [PIPE].
  [16] TXELECLDLE — TX elec idle (TxElecIdle) For field definition, refer to Table 5-3 of [PIPE].
  [15] RXPOLARITY — RX polarity (RxPolarity) For field definition, refer to Table 5-3 of [PIPE].
  [14] TXDETRXLOOPBACK — TX detect RX/loopback (TxDetRxLoopback) For field definition, refer to Table 5-3 of [PIPE].
  [13:11] LTDBPHYCMDSTATE — LTSSM PHY command state (LTDBPhyCmdState)
    0=PHY_IDLE (PHY command state is in IDLE. No PHY request pending); 1=PHY_DET (request to start receiver detection); 2=PHY_DET_3 (wait for Phy_Status (receiver detection)); 3=PHY_PWR_DLY (delay Pipe3_PowerDown P0 - P1/P2/P3 request); 4=PHY_PWR_A (delay for internal logic); 5=PHY_PWR_B (wait for Phy_Status(power state change request))
  [10:9] POWERDOWN — POWERDOWN (PowerDown) For field definition, refer to Table 5-3 of [PIPE].
  [8] RXEQTRAIN — RxEq train For field definition, refer to Table 5-3 of [PIPE].
  [7:6] TXDEEMPHASIS — TXDEEMPHASIS (TxDeemphasis) For field definition, refer to Table 5-3 of [PIPE].
  [5:3] LTDBCLKSTATE — LTSSM clock state (LTDBClkState) In multi-port host configuration, the port number is defined by Port-Select[3:0] field in the GDBGFIFOSPACE register. Note: GDBGLTSSM register is not applicable for USB 2.0-only mode.
    0=CLK_NORM (PHY is in non-P3 state and PCLK is running); 1=CLK_TO_P3 (P3 entry request to PHY);; 2=CLK_WAIT1 (wait for Phy_Status (P3 request));; 3=CLK_P3 (PHY is in P3 and PCLK is not running);; 4=CLK_TO_P0 (P3 exit request to PHY);; 5=CLK_WAIT2 (wait for Phy_Status (P3 exit request))
  [2] TXSWING — TX swing (TxSwing) For field definition, refer to Table 5-3 of [PIPE].
  [1] RXTERMINATION — RX termination (RxTermination)
  [0] TXONESZEROS — TX Ones/Zeros (TxOnesZeros) For field definition, refer to Table 5-3 of [PIPE].
0xC168 USB3DR_GBL_GDBGLNMCC ro — USB3DR global debug LNMCC register
  [8:0] LNMCC_BERC — This field indicates the bit error rate information for the port selected in the GDBGFIFOSPACE.PortSelect field. This field is for debug purposes only.
0xC16C USB3DR_GBL_GDBGBMU ro — USB3DR global debug BMU register
  [31:8] BMU_BCU — BMU_BCU debug information
  [7:4] BMU_DCU — BMU_DCU debug information
  [3:0] BMU_CCU — BMU_CCU debug information
0xC170 USB3DR_GBL_GDBGLSPMUX_HST reset 0x3F0000 — USB3DR global debug LSP MUX register - host
  [23:16] LOGIC_ANALYZER_TRACE — logic_analyzer_trace port MUX select Currently only bits[21:16] are used. A value of 0x3F drives 0s on the logic_analyzer_trace signal. This feature can be used if, instead of using a mux, this signal is intended to be ORed with other trace signals in the system to generate a common trace signal.
  [13:0] HOSTSELECT — Device LSP select Selects the LSP debug information presented in the GDBGLSP register in host mode.
0xC174 USB3DR_GBL_GDBGLSP ro — USB3DR global debug LSP register
  [31:0] LSPDEBUG — LSP Debug Information
0xC178 USB3DR_GBL_GDBGEPINFO0 ro — USB3DR global debug endpoint information register 0
  [31:0] EPDEBUG — Endpoint debug information, bits[31:0]
0xC17C USB3DR_GBL_GDBGEPINFO1 ro reset 0x800000 — USB3DR global debug endpoint information register 1
  [31:0] EPDEBUG — Endpoint debug information, bits[63:32]
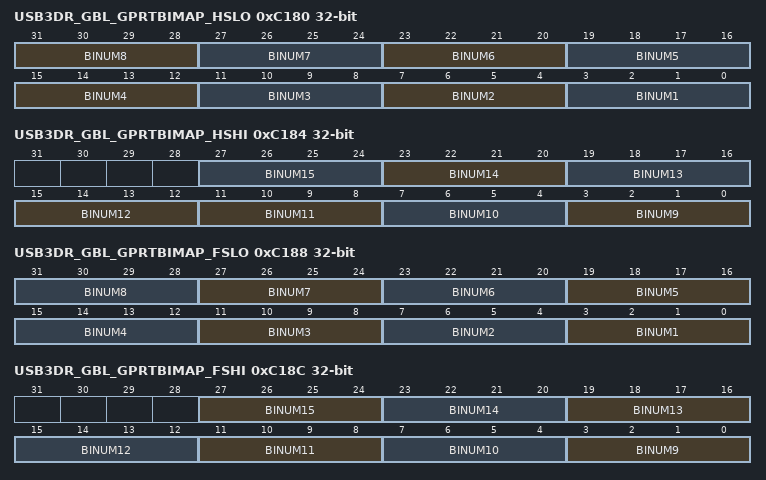
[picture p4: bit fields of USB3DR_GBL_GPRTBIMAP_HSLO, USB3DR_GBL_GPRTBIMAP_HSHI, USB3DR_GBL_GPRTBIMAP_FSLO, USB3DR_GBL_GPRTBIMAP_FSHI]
0xC180 USB3DR_GBL_GPRTBIMAP_HSLO — USB3DR global high-speed port to bus instance mapping register - low
  [31:28] BINUM8 — BINUM8: HS USB instance number for port 8. Application programmable ID field.
  [27:24] BINUM7 — BINUM7: HS USB instance number for port 7. Application programmable ID field.
  [23:20] BINUM6 — BINUM6 USB instance number for port 6. Application programmable ID field.
  [4n-1:4n-4] BINUM{n} (n=1..5) — BINUM{n}: HS USB instance number for port {n}. Application programmable ID field.
0xC184 USB3DR_GBL_GPRTBIMAP_HSHI (reset mask 0xF0000000) — USB3DR global high-speed port to bus instance mapping register - high
  [4n-33:4n-36] BINUM{n} (n=12..15) — BINUM{n}: HS USB instance number for port {n}. Application programmable ID field.
  [11:8] BINUM11 — BINUM11: HS USB Instance Number for 11. Application programmable ID field.
  [7:4] BINUM10 — BINUM10: HS USB instance number for port 10. Application programmable ID field.
  [3:0] BINUM9 — BINUM9: HS USB instance number for port 9. Application programmable ID field.
0xC188 USB3DR_GBL_GPRTBIMAP_FSLO — USB3DR global full-speed port to bus instance mapping register - low
  [4n-1:4n-4] BINUM{n} (n=1..8) — BINUM{n}: FS USB instance number for port {n}. Application programmable ID field.
0xC18C USB3DR_GBL_GPRTBIMAP_FSHI (reset mask 0xF0000000) — USB3DR global full-speed port to bus instance mapping register - high
  [4n-33:4n-36] BINUM{n} (n=9..15) — BINUM{n}: FS USB instance number for port {n}. Application programmable ID field.
